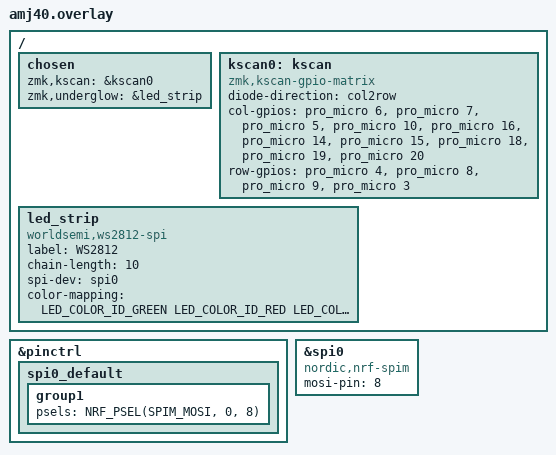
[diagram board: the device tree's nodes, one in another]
/* Archivo: amj40.overlay */

#include <zephyr/dt-bindings/zmk/matrix_transform.h>

/ {
    // Elige el "kscan" (escaneo de teclado) que usaremos.
    chosen {
        zmk,kscan = &kscan0;
    };

    // Define el servicio de escaneo de la matriz.
    kscan0: kscan {
        compatible = "zmk,kscan-gpio-matrix";
        
        // IMPORTANTE: Dirección de los diodos.
        // "col2row" es lo más común. Si las teclas no responden, cambia a "row2col".
        diode-direction = "col2row";

        // --- ¡EDITA ESTA SECCIÓN CON TUS PINES! ---
        // Lista de los pines del microcontrolador conectados a las COLUMNAS.
        col-gpios
            = <&pro_micro 6 (GPIO_ACTIVE_HIGH)>  // Col 0
            , <&pro_micro 7 (GPIO_ACTIVE_HIGH)>  // Col 1
            , <&pro_micro 5 (GPIO_ACTIVE_HIGH)>  // Col 2
            , <&pro_micro 10 (GPIO_ACTIVE_HIGH)>  // Col 3
            , <&pro_micro 16 (GPIO_ACTIVE_HIGH)>  // Col 4
            , <&pro_micro 14 (GPIO_ACTIVE_HIGH)>  // Col 5
            , <&pro_micro 15 (GPIO_ACTIVE_HIGH)>  // Col 6
            , <&pro_micro 18 (GPIO_ACTIVE_HIGH)>  // Col 7
            , <&pro_micro 19 (GPIO_ACTIVE_HIGH)>   // Col 8
            , <&pro_micro 20 (GPIO_ACTIVE_HIGH)>   // Col 9
            ;

        // Lista de los pines del microcontrolador conectados a las FILAS.
        row-gpios
            = <&pro_micro 4 (GPIO_ACTIVE_HIGH)>   // Fila 0 (la de arriba)
            , <&pro_micro 8 (GPIO_ACTIVE_HIGH)>   // Fila 1
            , <&pro_micro 9 (GPIO_ACTIVE_HIGH)>   // Fila 2
            , <&pro_micro 3 (GPIO_ACTIVE_HIGH)>   // Fila 3
            ;
        // --- FIN DE LA SECCIÓN DE PINES ---
    };
};
&pinctrl {
    spi0_default: spi0_default {
        group1 {
            // ¡EDITA ESTE PIN! Usa el pin al que conectaste la DATA de los LEDs.
            // Este es solo un ejemplo usando el pin 8 (P0.08).
            psels = <NRF_PSEL(SPIM_MOSI, 0, 8)>;
        };
    };
};

&spi0 {
    compatible = "nordic,nrf-spim";
    status = "okay";
    mosi-pin = <8>; // El mismo número de pin que usaste arriba.
};

/ {
    // Dentro de la sección raíz, añade la definición de la tira de LEDs.
    chosen {
        // ... (la línea zmk,kscan = &kscan0; ya debería estar aquí) ...
        zmk,underglow = &led_strip; // Le decimos a ZMK que use nuestra tira de LEDs.
    };

    led_strip: led_strip {
        compatible = "worldsemi,ws2812-spi";
        label = "WS2812";

        // Conecta la tira al bus SPI que definimos arriba.
        chain-length = <10>; // ¡EDITA ESTO! El número total de LEDs en tu tira.
        spi-dev = <&spi0>;
        color-mapping = <
            LED_COLOR_ID_GREEN
            LED_COLOR_ID_RED
            LED_COLOR_ID_BLUE
        >;
    };
};
